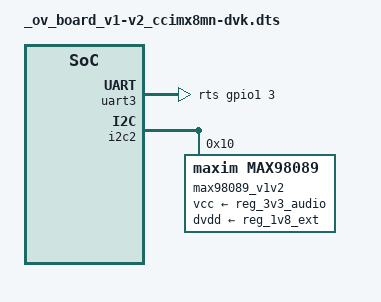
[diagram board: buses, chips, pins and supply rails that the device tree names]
/*
 * Copyright 2020 Digi International Inc.
 *
 * Permission to use, copy, modify, and/or distribute this software for any
 * purpose with or without fee is hereby granted, provided that the above
 * copyright notice and this permission notice appear in all copies.
 * THE SOFTWARE IS PROVIDED "AS IS" AND THE AUTHOR DISCLAIMS ALL WARRANTIES
 * WITH REGARD TO THIS SOFTWARE INCLUDING ALL IMPLIED WARRANTIES OF
 * MERCHANTABILITY AND FITNESS. IN NO EVENT SHALL THE AUTHOR BE LIABLE FOR
 * ANY SPECIAL, DIRECT, INDIRECT, OR CONSEQUENTIAL DAMAGES OR ANY DAMAGES
 * WHATSOEVER RESULTING FROM LOSS OF USE, DATA OR PROFITS, WHETHER IN AN
 * ACTION OF CONTRACT, NEGLIGENCE OR OTHER TORTIOUS ACTION, ARISING OUT OF
 * OR IN CONNECTION WITH THE USE OR PERFORMANCE OF THIS SOFTWARE.
 */

 #include <dt-bindings/gpio/gpio.h>
 #include <dt-bindings/clock/imx8mn-clock.h>

/dts-v1/;
/plugin/;

/ {
	fragment@0 {
		target-path = "/";
		__overlay__ {
			overlay-description = "DVK: version <= 2";
		};
	};

	fragment@1 {
		target = <&lt_bridge>;
		__overlay__ {
			/*
			 * A hardware design issue on the DVK version <=2 makes the
			 * hotplug detect line not usable.
			 */
			pinctrl-0 = <&pinctrl_lt8912>;
			no-hpd;
		};
	};

	fragment@2 {
		target = <&uart3>;
		__overlay__ {
			/*
			 * On the DVK version <=2 a different gpio is used to
			 * control the RS485 RE#/DE line.
			 *
			 * RS-485 mode (comment these lines to use this UART in
			 * RS232 mode)
			 */
			pinctrl-0 = <&pinctrl_uart3_rs485>,
				    <&pinctrl_uart3_rs485_re_v1_v2>;
			rts-gpios = <&gpio1 3 GPIO_ACTIVE_HIGH>;
		};
	};

	/* Audio codec on DVK v1 and v2 was connected to I2C2 */
	fragment@3 {
		target = <&i2c2>;
		__overlay__ {
			#address-cells = <1>;
			#size-cells = <0>;

			max98089_v1v2: codec@10 {
				compatible = "maxim,max98089";
				reg = <0x10>;
				clocks = <&clk IMX8MN_CLK_SAI2_ROOT>;
				clock-names = "mclk";
				vcc-supply = <&reg_3v3_audio>;
				dvdd-supply = <&reg_1v8_ext>;
				/*
				 * NOTE: The max98089 sound codec uses the same
				 * I2C address than the fusion touch controller
				 * If using the Fusion on a DVK v1 or v2,
				 * disable this node by uncommenting the
				 * following line:
				 */
				 //status = "disabled";
			};
		};
	};

	fragment@4 {
		target = <&sound_max98089>;
		__overlay__ {
			audio-codec = <&max98089_v1v2>;
		};
	};

	/* Disable the audio codec on I2C3 (default on DVK >= v3) */
	fragment@5 {
		target = <&max98089>;
		__overlay__ {
			status = "disabled";
		};
	};
};
